AUTOSAR XML (schema 4-2-2)
package /ComponentTypes
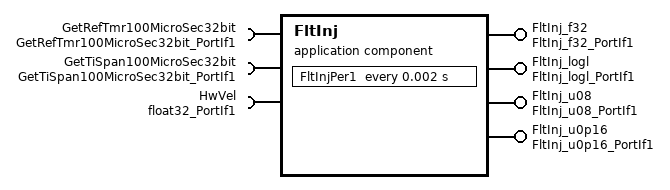
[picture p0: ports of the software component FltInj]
  application sw component type FltInj
    4 x provide port, all with server-com-spec{operation=Oper, queue-length=1}:
      FltInj_f32: provided-interface=FltInj_f32_PortIf1
      FltInj_logl: provided-interface=FltInj_logl_PortIf1
      FltInj_u08: provided-interface=FltInj_u08_PortIf1
      FltInj_u0p16: provided-interface=FltInj_u0p16_PortIf1
    require port GetRefTmr100MicroSec32bit: client-com-spec=Oper, required-interface=GetRefTmr100MicroSec32bit_PortIf1
    require port GetTiSpan100MicroSec32bit: client-com-spec=Oper, required-interface=GetTiSpan100MicroSec32bit_PortIf1
    require port HwVel: nonqueued-receiver-com-spec{data-element=Val, filter=data-filter-type=ALWAYS, init-value=0}, required-interface=float32_PortIf1
    behavior FltInj_InternalBehavior
      4 x operation invoked event:
        OIT_FltInj_f32_Oper_FltInj_f32_Oper: start-on-event=FltInj_f32_Oper, operation=FltInj_f32.Oper
        OIT_FltInj_logl_Oper_FltInj_logl_Oper: start-on-event=FltInj_logl_Oper, operation=FltInj_logl.Oper
        OIT_FltInj_u08_Oper_FltInj_u08_Oper: start-on-event=FltInj_u08_Oper, operation=FltInj_u08.Oper
        OIT_FltInj_u0p16_Oper_FltInj_u0p16_Oper: start-on-event=FltInj_u0p16_Oper, operation=FltInj_u0p16.Oper
      timing event TMT_FltInjPer1: start-on-event=FltInjPer1, period=0.002
      5 x runnable:
        FltInj_f32_Oper: can-be-invoked-concurrently=true
        FltInj_logl_Oper: can-be-invoked-concurrently=true
        FltInj_u08_Oper: can-be-invoked-concurrently=true
        FltInj_u0p16_Oper: can-be-invoked-concurrently=true
        FltInjPer1
          data-receive-point-by-arguments:
            access REC_HwVel_Val: accessed-variable=HwVel.Val
          sync call SC_GetRefTmr100MicroSec32bit_Oper: operation=GetRefTmr100MicroSec32bit.Oper, timeout=0
          sync call SC_GetTiSpan100MicroSec32bit_Oper: operation=GetTiSpan100MicroSec32bit.Oper, timeout=0
  swc implementation FltInj_Implementation: behavior=FltInj_InternalBehavior
    code-descriptors:
      code Default: artifact-descriptors=autosar-engineering-object={short-label=Default, category=SWSRC}
